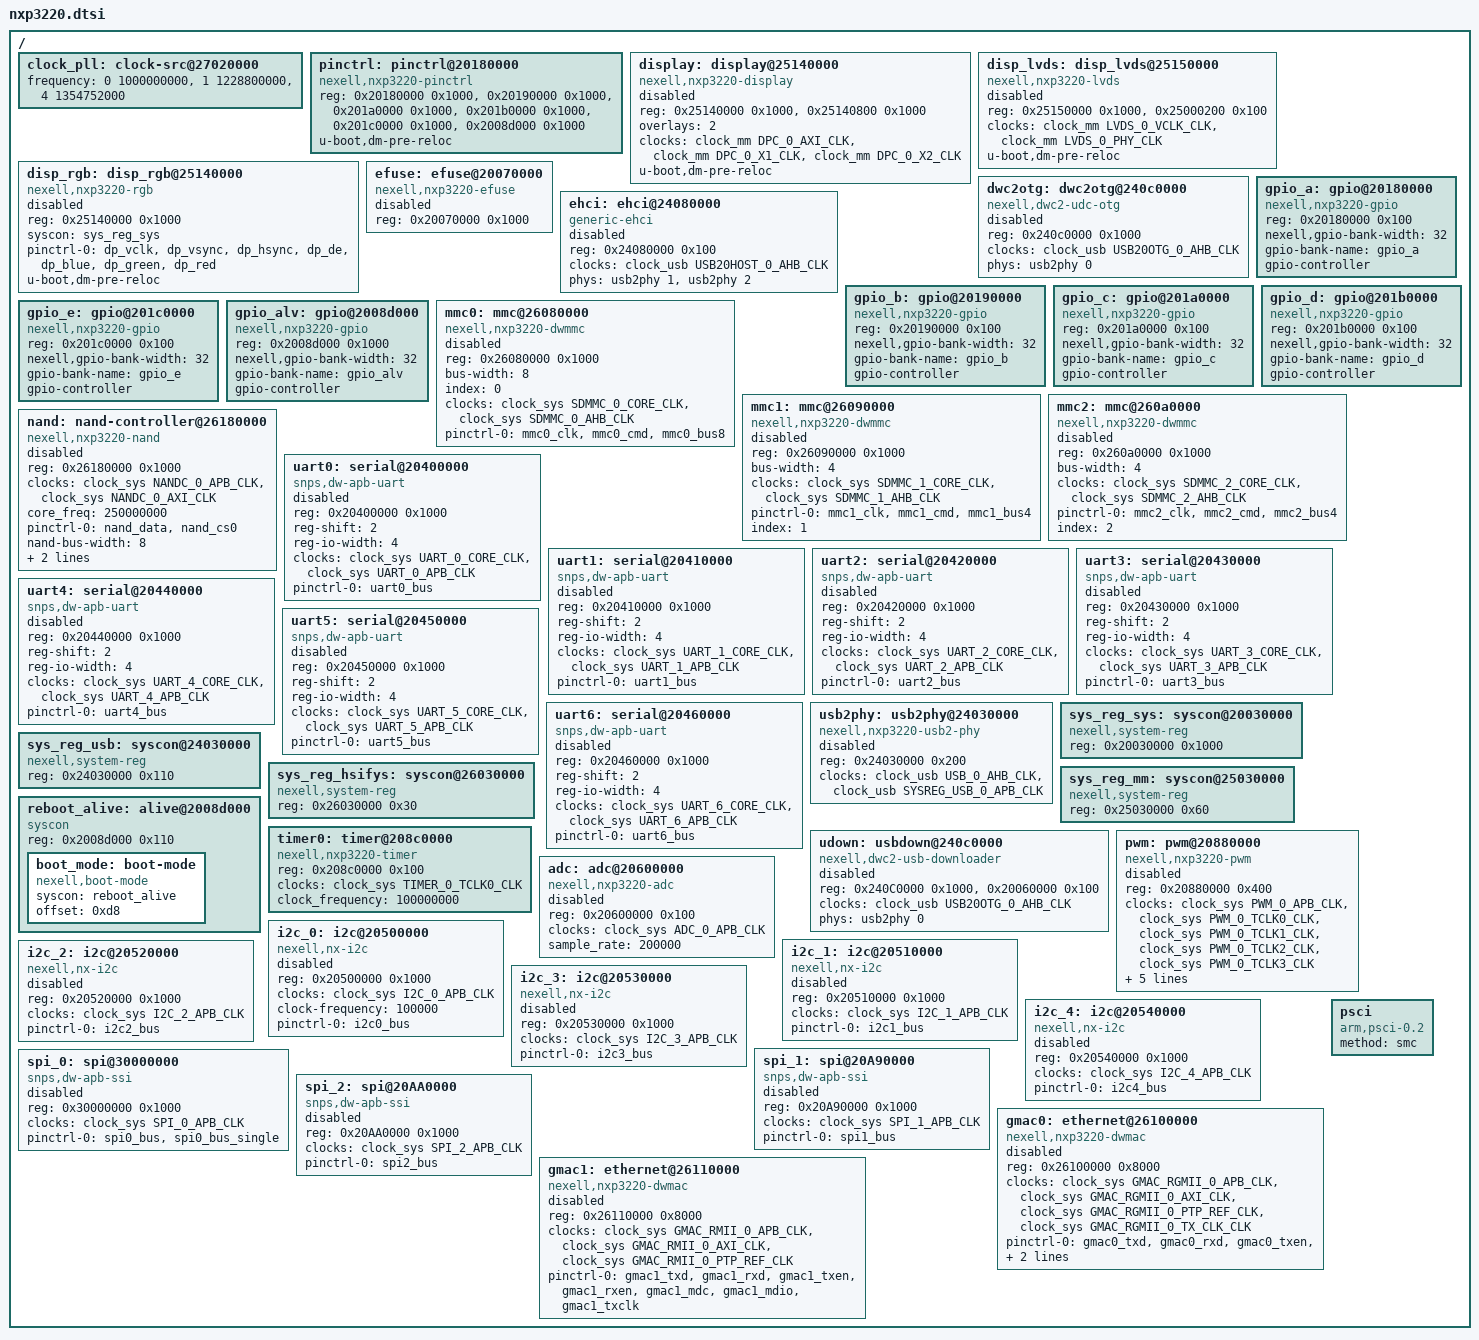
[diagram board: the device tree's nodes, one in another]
/*
 * (C) Copyright 2018 Nexell
 * Jongkeun, Choi <jkchoi@nexell.co.kr>
 *
 * SPDX-License-Identifier:      GPL-2.0+
 */

#include "skeleton.dtsi"
#include <dt-bindings/clock/nxp3220-clk.h>
#include <dt-bindings/video/nexell.h>

/ {
	#include "nxp3220-clk.dtsi"

        clock_pll: clock-src@27020000 {
                frequency = <0 1000000000>, /* for system bus */
			    <1 1228800000>, /* for Audio 48Khz */
			    <4 1354752000>; /* for Audio 44.1Khz */
        };

	pinctrl: pinctrl@20180000 {
		compatible = "nexell,nxp3220-pinctrl";
		reg = <0x20180000 0x1000>,
		      <0x20190000 0x1000>,
		      <0x201a0000 0x1000>,
		      <0x201b0000 0x1000>,
		      <0x201c0000 0x1000>,
		      <0x2008d000 0x1000>;
		reg-names = "gpioa", "gpiob", "gpioc", "gpiod", "gpioe",
		            "alive";
		u-boot,dm-pre-reloc;
	};

	display: display@25140000 {
		compatible = "nexell,nxp3220-display";
     		reg = <0x25140000 0x1000>, <0x25140800 0x1000>;
     		overlays = <2>;
		clocks = <&clock_mm DPC_0_AXI_CLK>,
			<&clock_mm DPC_0_X1_CLK>,
			<&clock_mm DPC_0_X2_CLK>;
		clock-names = "axi", "clk_x1", "clk_x2";
		u-boot,dm-pre-reloc;
		status = "disabled";
	};

	disp_lvds: disp_lvds@25150000 {
		compatible = "nexell,nxp3220-lvds";
		reg = <0x25150000 0x1000>, <0x25000200 0x100>;
		clocks = <&clock_mm LVDS_0_VCLK_CLK>,
			<&clock_mm LVDS_0_PHY_CLK>;
		clock-names = "vclk", "phy";
		u-boot,dm-pre-reloc;
		status = "disabled";
	};

	disp_rgb: disp_rgb@25140000 {
		compatible = "nexell,nxp3220-rgb";
		reg = <0x25140000 0x1000>;
		syscon = <&sys_reg_sys>;
		pinctrl-names = "default";
		pinctrl-0 = <&dp_vclk &dp_vsync &dp_hsync &dp_de &dp_blue &dp_green &dp_red>;
		u-boot,dm-pre-reloc;
		status = "disabled";
	};

	dwc2otg: dwc2otg@240c0000 {
		#address-cells = <1>;
		#size-cells = <1>;
		compatible = "nexell,dwc2-udc-otg";
		reg = <0x240c0000 0x1000>;
		clocks = <&clock_usb USB20OTG_0_AHB_CLK>;
		phys = <&usb2phy 0>;
		status = "disabled";
	};

	efuse: efuse@20070000 {
		compatible = "nexell,nxp3220-efuse";
		reg = <0x20070000 0x1000>;
		status = "disabled";
	};

	ehci: ehci@24080000 {
		compatible = "generic-ehci";
		reg = <0x24080000 0x100>;
		clocks = <&clock_usb USB20HOST_0_AHB_CLK>;
		phys = <&usb2phy 1>, <&usb2phy 2>;
		phy-names = "usb0", "usb1";
		status = "disabled";
	};

	gpio_a: gpio@20180000 {
		compatible = "nexell,nxp3220-gpio";
		reg = <0x20180000 0x100>;
		nexell,gpio-bank-width = <32>;
		gpio-bank-name = "gpio_a";
		gpio-controller;
		#gpio-cells = <2>;
	};

	gpio_b: gpio@20190000 {
		compatible = "nexell,nxp3220-gpio";
		reg = <0x20190000 0x100>;
		nexell,gpio-bank-width = <32>;
		gpio-bank-name = "gpio_b";
		gpio-controller;
		#gpio-cells = <2>;
	};

	gpio_c: gpio@201a0000 {
		compatible = "nexell,nxp3220-gpio";
		reg = <0x201a0000 0x100>;
		nexell,gpio-bank-width = <32>;
		gpio-bank-name = "gpio_c";
		gpio-controller;
		#gpio-cells = <2>;
	};

	gpio_d: gpio@201b0000 {
		compatible = "nexell,nxp3220-gpio";
		reg = <0x201b0000 0x100>;
		nexell,gpio-bank-width = <32>;
		gpio-bank-name = "gpio_d";
		gpio-controller;
		#gpio-cells = <2>;
	};

	gpio_e: gpio@201c0000 {
		compatible = "nexell,nxp3220-gpio";
		reg = <0x201c0000 0x100>;
		nexell,gpio-bank-width = <32>;
		gpio-bank-name = "gpio_e";
		gpio-controller;
		#gpio-cells = <2>;
	};

	gpio_alv: gpio@2008d000 {
		compatible = "nexell,nxp3220-gpio";
		reg = <0x2008d000 0x1000>;
		nexell,gpio-bank-width = <32>;
		gpio-bank-name = "gpio_alv";
		gpio-controller;
		#gpio-cells = <2>;
	};


	mmc0: mmc@26080000 {
                #address-cells = <1>;
                #size-cells = <0>;
                compatible = "nexell,nxp3220-dwmmc";
                reg = <0x26080000 0x1000>;
                bus-width = <8>;
                index = <0>;
                clocks = <&clock_sys SDMMC_0_CORE_CLK>,
                        <&clock_sys SDMMC_0_AHB_CLK>;
		pinctrl-names = "default";
		pinctrl-0 = <&mmc0_clk &mmc0_cmd &mmc0_bus8>;
                status = "disabled";
        };

        mmc1: mmc@26090000 {
                #address-cells = <1>;
                #size-cells = <0>;
                compatible = "nexell,nxp3220-dwmmc";
                reg = <0x26090000 0x1000>;
                bus-width = <4>;
                clocks = <&clock_sys SDMMC_1_CORE_CLK>,
                        <&clock_sys SDMMC_1_AHB_CLK>;
		pinctrl-names = "default";
		pinctrl-0 = <&mmc1_clk &mmc1_cmd &mmc1_bus4>;
                index = <1>;
                status = "disabled";
        };

        mmc2: mmc@260a0000 {
                #address-cells = <1>;
                #size-cells = <0>;
                compatible = "nexell,nxp3220-dwmmc";
                reg = <0x260a0000 0x1000>;
                bus-width = <4>;
                clocks = <&clock_sys SDMMC_2_CORE_CLK>,
                        <&clock_sys SDMMC_2_AHB_CLK>;
		pinctrl-names = "default";
		pinctrl-0 = <&mmc2_clk &mmc2_cmd &mmc2_bus4>;
                index = <2>;
                status = "disabled";
        };

	nand: nand-controller@26180000 {
		compatible = "nexell,nxp3220-nand";
		reg = <0x26180000 0x1000>;
		clocks = <&clock_sys NANDC_0_APB_CLK>,
			 <&clock_sys NANDC_0_AXI_CLK>;
		clock-names = "nand_apb", "nand_core";
		core_freq = <250000000>;
		pinctrl-names = "default";
		pinctrl-0 = <&nand_data>, <&nand_cs0>;
		nand-bus-width = <8>;
		nand-on-flash-bbt;
		nand-ecc-mode = "hw_syndrome";
		status = "disabled";
	};

	uart0: serial@20400000 {
		compatible = "snps,dw-apb-uart";
		reg = <0x20400000 0x1000>;
		reg-shift = <2>;
		reg-io-width = <4>;
		clocks = <&clock_sys UART_0_CORE_CLK>,
		      <&clock_sys UART_0_APB_CLK >;
		clock-names = "baudclk", "apb_pclk";
		pinctrl-names = "default";
		pinctrl-0 = <&uart0_bus>;
		status = "disabled";
	};

	uart1: serial@20410000 {
		compatible = "snps,dw-apb-uart";
		reg = <0x20410000 0x1000>;
		reg-shift = <2>;
		reg-io-width = <4>;
		clocks = <&clock_sys UART_1_CORE_CLK>,
		      <&clock_sys UART_1_APB_CLK >;
		clock-names = "baudclk", "apb_pclk";
		pinctrl-names = "default";
		pinctrl-0 = <&uart1_bus>;

		status = "disabled";
	};

	uart2: serial@20420000 {
		compatible = "snps,dw-apb-uart";
		reg = <0x20420000 0x1000>;
		reg-shift = <2>;
		reg-io-width = <4>;
		clocks = <&clock_sys UART_2_CORE_CLK>,
		      <&clock_sys UART_2_APB_CLK >;
		clock-names = "baudclk", "apb_pclk";
		pinctrl-names = "default";
		pinctrl-0 = <&uart2_bus>;
		status = "disabled";
	};

	uart3: serial@20430000 {
		compatible = "snps,dw-apb-uart";
		reg = <0x20430000 0x1000>;
		reg-shift = <2>;
		reg-io-width = <4>;
		clocks = <&clock_sys UART_3_CORE_CLK>,
		      <&clock_sys UART_3_APB_CLK >;
		clock-names = "baudclk", "apb_pclk";
		pinctrl-names = "default";
		pinctrl-0 = <&uart3_bus>;
		status = "disabled";
	};

	uart4: serial@20440000 {
		compatible = "snps,dw-apb-uart";
		reg = <0x20440000 0x1000>;
		reg-shift = <2>;
		reg-io-width = <4>;
		clocks = <&clock_sys UART_4_CORE_CLK>,
		      <&clock_sys UART_4_APB_CLK >;
		clock-names = "baudclk", "apb_pclk";
		pinctrl-names = "default";
		pinctrl-0 = <&uart4_bus>;
		status = "disabled";
	};

	uart5: serial@20450000 {
		compatible = "snps,dw-apb-uart";
		reg = <0x20450000 0x1000>;
		reg-shift = <2>;
		reg-io-width = <4>;
		clocks = <&clock_sys UART_5_CORE_CLK>,
		      <&clock_sys UART_5_APB_CLK >;
		clock-names = "baudclk", "apb_pclk";
		pinctrl-names = "default";
		pinctrl-0 = <&uart5_bus>;
		status = "disabled";
	};

	uart6: serial@20460000 {
		compatible = "snps,dw-apb-uart";
		reg = <0x20460000 0x1000>;
		reg-shift = <2>;
		reg-io-width = <4>;
		clocks = <&clock_sys UART_6_CORE_CLK>,
		      <&clock_sys UART_6_APB_CLK >;
		clock-names = "baudclk", "apb_pclk";
		pinctrl-names = "default";
		pinctrl-0 = <&uart6_bus>;
		status = "disabled";
	};

	usb2phy: usb2phy@24030000 {
		compatible = "nexell,nxp3220-usb2-phy";
		reg = <0x24030000 0x200>;
		#phy-cells = <1>;
		clocks = <&clock_usb USB_0_AHB_CLK>,
		         <&clock_usb SYSREG_USB_0_APB_CLK>;
		clock-names = "ahb", "apb";
		status = "disabled";
	};

	sys_reg_sys: syscon@20030000 {
		compatible = "nexell,system-reg","syscon", "simple-mfd";
		reg = <0x20030000 0x1000>;
	};

	sys_reg_usb: syscon@24030000 {
		compatible = "nexell,system-reg","syscon", "simple-mfd";
		reg = <0x24030000 0x110>;
	};

	sys_reg_hsifys: syscon@26030000 {
		compatible = "nexell,system-reg","syscon", "simple-mfd";
		reg = <0x26030000 0x30>;
	};

	sys_reg_mm: syscon@25030000 {
		compatible = "nexell,system-reg","syscon", "simple-mfd";
		reg = <0x25030000 0x60>;
	};

	reboot_alive: alive@2008d000 {
		compatible = "syscon", "simple-mfd";
		reg = <0x2008d000 0x110>;

		boot_mode: boot-mode {
			compatible = "nexell,boot-mode";
			syscon = <&reboot_alive>;
			offset = <0xd8>;        /* ALIVE_SCRATCHRSTREG4 */
		};
	};

	timer0: timer@208c0000 {
		compatible = "nexell,nxp3220-timer";
		reg = <0x208c0000 0x100>;
		clocks = <&clock_sys TIMER_0_TCLK0_CLK>;
		clock-names = "timer0";
		clock_frequency = <100000000>;
	};

	udown: usbdown@240c0000 {
		#address-cells = <1>;
		#size-cells = <1>;
		compatible = "nexell,dwc2-usb-downloader";
		reg = <0x240C0000 0x1000>, <0x20060000 0x100>;
		clocks = <&clock_usb USB20OTG_0_AHB_CLK>;
		phys = <&usb2phy 0>;
		status = "disabled";
	};

	pwm: pwm@20880000 {
		compatible = "nexell,nxp3220-pwm";
		reg = <0x20880000 0x400>;
		#pwm-cells = <3>;
		clocks = <&clock_sys PWM_0_APB_CLK>,
			 <&clock_sys PWM_0_TCLK0_CLK>,
			 <&clock_sys PWM_0_TCLK1_CLK>,
			 <&clock_sys PWM_0_TCLK2_CLK>,
			 <&clock_sys PWM_0_TCLK3_CLK>;
		clock-names = "pwm_apb", "pwm_tclk0", "pwm_tclk1", "pwm_tclk2",
			      "pwm_tclk3";
		pwm-outputs = <0>, <1>, <2>, <3>;
		tclk_freq = <100000000>, <100000000>, <100000000>, <100000000>;
		pinctrl-names = "default";
		pinctrl-0 = <&pwm0_pin &pwm1_pin &pwm2_pin &pwm3_pin>;
		status = "disabled";
	};

	adc: adc@20600000 {
		compatible = "nexell,nxp3220-adc";
		reg = <0x20600000 0x100>;
		clocks = <&clock_sys ADC_0_APB_CLK>;
		clock-names = "adc";
		sample_rate = <200000>;
		status = "disabled";
	};

	i2c_0: i2c@20500000 {
		compatible = "nexell,nx-i2c";
		reg = <0x20500000 0x1000>;
		clocks =<&clock_sys I2C_0_APB_CLK>;
		clock-names = "i2c0_apb";
		clock-frequency = <100000>;
		pinctrl-names = "default";
		pinctrl-0 = <&i2c0_bus>;
		status = "disabled";
	};

	i2c_1: i2c@20510000 {
		compatible = "nexell,nx-i2c";
		reg = <0x20510000 0x1000>;
		clocks =<&clock_sys I2C_1_APB_CLK>;
		clock-names = "i2c1_apb";
		pinctrl-names = "default";
		pinctrl-0 = <&i2c1_bus>;
		status = "disabled";
	};

	i2c_2: i2c@20520000 {
		compatible = "nexell,nx-i2c";
		reg = <0x20520000 0x1000>;
		clocks =<&clock_sys I2C_2_APB_CLK>;
		clock-names = "i2c2_apb";
		pinctrl-names = "default";
		pinctrl-0 = <&i2c2_bus>;
		status = "disabled";
	};

	i2c_3: i2c@20530000 {
		compatible = "nexell,nx-i2c";
		reg = <0x20530000 0x1000>;
		clocks =<&clock_sys I2C_3_APB_CLK>;
		clock-names = "i2c3_apb";
		pinctrl-names = "default";
		pinctrl-0 = <&i2c3_bus>;
		status = "disabled";
	};

	i2c_4: i2c@20540000 {
		compatible = "nexell,nx-i2c";
		reg = <0x20540000 0x1000>;
		clocks =<&clock_sys I2C_4_APB_CLK>;
		clock-names = "i2c4_apb";
		pinctrl-names = "default";
		pinctrl-0 = <&i2c4_bus>;
		status = "disabled";
	};

	spi_0: spi@30000000 {
		compatible = "snps,dw-apb-ssi";
		reg = <0x30000000 0x1000>;
		clocks =<&clock_sys SPI_0_APB_CLK>;
		clock-names = "spi0_apb";
		pinctrl-names = "default";
		pinctrl-0 = <&spi0_bus>, <&spi0_bus_single>;
		#address-cells = <1>;
		#size-cells = <0>;
		status = "disabled";
	};

	spi_1: spi@20A90000 {
		compatible = "snps,dw-apb-ssi";
		reg = <0x20A90000 0x1000>;
		clocks =<&clock_sys SPI_1_APB_CLK>;
		clock-names = "spi1_apb";
		pinctrl-names = "default";
		pinctrl-0 = <&spi1_bus>;
		#address-cells = <1>;
		#size-cells = <0>;
		status = "disabled";
	};

	spi_2: spi@20AA0000 {
		compatible = "snps,dw-apb-ssi";
		reg = <0x20AA0000 0x1000>;
		clocks =<&clock_sys SPI_2_APB_CLK>;
		clock-names = "spi2_apb";
		pinctrl-names = "default";
		pinctrl-0 = <&spi2_bus>;
		#address-cells = <1>;
		#size-cells = <0>;
		status = "disabled";
	};

	gmac0: ethernet@26100000 {
		compatible = "nexell,nxp3220-dwmac";
		reg = <0x26100000 0x8000>;
		clocks = <&clock_sys GMAC_RGMII_0_APB_CLK>,
			 <&clock_sys GMAC_RGMII_0_AXI_CLK>,
			 <&clock_sys GMAC_RGMII_0_PTP_REF_CLK>,
			 <&clock_sys GMAC_RGMII_0_TX_CLK_CLK>;
		clock-names = "slave_bus", "master_bus", "ptp_ref", "tx";
		pinctrl-names = "default";
		pinctrl-0 = <&gmac0_txd>, <&gmac0_rxd>, <&gmac0_txen>,
			    <&gmac0_rxen>, <&gmac0_mdc>, <&gmac0_mdio>,
			    <&gmac0_rxclk>, <&gmac0_txclk>;
		status = "disabled";
	};

	gmac1: ethernet@26110000 {
		compatible = "nexell,nxp3220-dwmac";
		reg = <0x26110000 0x8000>;
		clocks = <&clock_sys GMAC_RMII_0_APB_CLK>,
			 <&clock_sys GMAC_RMII_0_AXI_CLK>,
			 <&clock_sys GMAC_RMII_0_PTP_REF_CLK>;
		clock-names = "slave_bus", "master_bus", "ptp_ref";
		pinctrl-names = "default";
		pinctrl-0 = <&gmac1_txd>, <&gmac1_rxd>, <&gmac1_txen>,
			    <&gmac1_rxen>, <&gmac1_mdc>, <&gmac1_mdio>,
			    <&gmac1_txclk>;
		status = "disabled";
	};

	psci {
		compatible = "arm,psci-0.2";
		method = "smc";
	};
};

#include "nxp3220-pinctrl.dtsi"
